# CY8C4247LQI_BL483 register map
File version: 0.1
PSoC 4200 BLE
Registers are 32-bit, read-write, no defined reset value unless marked. A register's access mark holds for its fields unless they carry their own. Offsets are from the block's base; lines under a group give offsets from that group; [hi:lo] are bit positions; {n}, {i} and the like mark numbered series; 'fields as' and 'values as' point back to an identical list; <NAME> marks a mode.

## Memory map
0x00000000 Opamp_1 — OpAmp
0x00000000 UART — Serial Communication Block
0x00000000 ADC_Timer
0x00000000 ADC_SAR_Seq — Sequencing SAR ADC
0x400F0002 PrISM_2 — PrISM
0x400F0003 PrISM_1 — PrISM

## Opamp_1 — OpAmp
Base 0x00000000
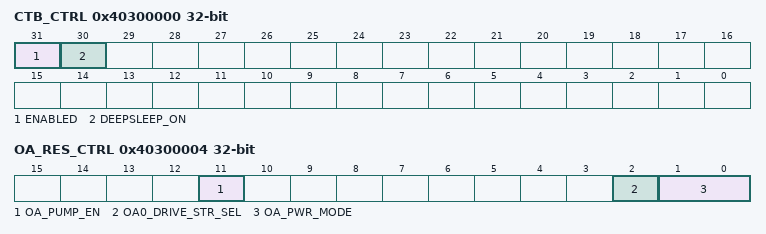
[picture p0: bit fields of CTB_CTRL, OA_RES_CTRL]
0x40300000 CTB_CTRL — Global CTB IP and power control
  [31] ENABLED — Selects component behavior in DeepSleep power mode
    0=DISABLE (CTB IP disabled (put analog in power down, open all switches)); 1=ENABLE (CTB IP enabledCTB IP enabled)
  [30] DEEPSLEEP_ON — Selects component behavior in DeepSleep power mode
    0=DISABLE (CTB IP disabled off during DeepSleep power mode); 1=ENABLE (CTB IP remains enabled during DeepSleep power mode (if ENABLED=1))
0x40300004 OA_RES_CTRL — Opamp and resistor control
  [11] OA_PUMP_EN — Selects pump
    0=DISABLE (Pump disabled); 1=ENABLE (Pump enabled)
  [2] OA0_DRIVE_STR_SEL — Opamp output strenght select
    0=Internal only; 1=Output to pin
  [1:0] OA_PWR_MODE — Selects power for opamp
    0=OFF; 1=LOW (Low power); 2=MED (Medium power); 3=HIGH (High power)
0x40300F08 OA_COMP_TRIM — Opamp Compenation Capacitor Trim
  [1:0] OA_COMP_TRIM
    1=HIGH_SPEED; 2=BALANCED; 3=HIGH_STABILITY

## ADC_Timer
Base 0x00000000
0x40200108 COUNTER — Current counter value
0x4020010C CC — Compare / capture value
0x40200110 CC_BUF — Compare / capture buffer value
0x40200114 PERIOD — Period value
0x40200118 PERIOD_BUF — Period buffer value

## PrISM_1 — PrISM
Base 0x400F0003
Same registers: PrISM_2 0x400F0002
0x00 PrISM_SEED 8-bit — Current seed value
0x10 PrISM_POLYNOM 8-bit — Polynomial
0x20 PrISM_DENSITY0 8-bit — Pulse Density 0
0x30 PrISM_DENSITY1 8-bit — Pulse Density 1
0x40 PrISM_SEED_COPY 8-bit — Start seed value
0x70 PrISM_CONTROL 3-bit — Control register
  [2] compare_type1 — XX
  [1] compare_type0
  [0] ctrl_enable
